AUTOSAR XML (schema 00045)
package /Esh
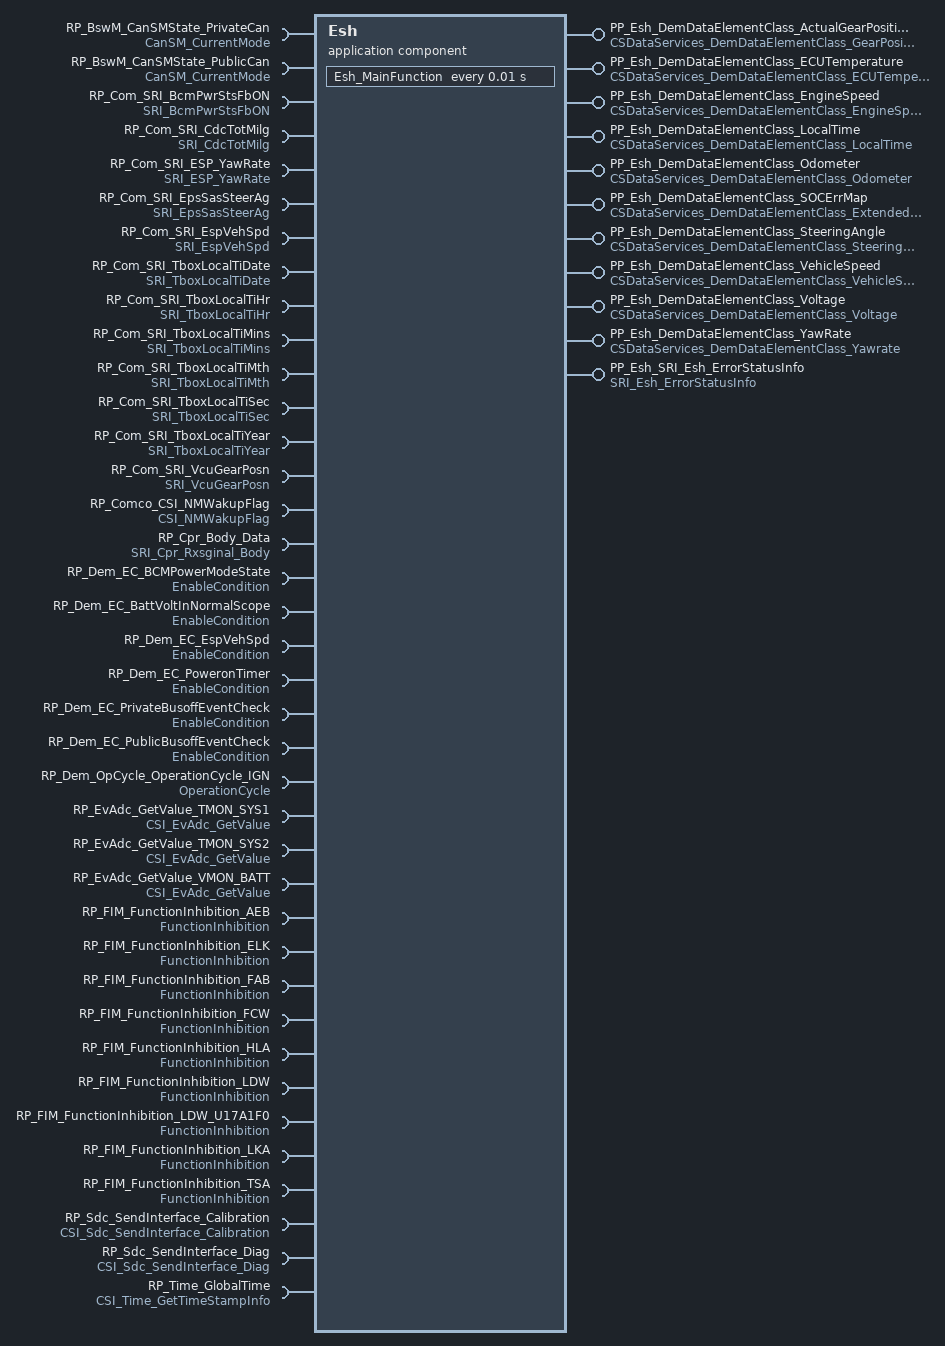
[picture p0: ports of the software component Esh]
  application sw component type Esh
    11 x provide port:
      PP_Esh_DemDataElementClass_ActualGearPosition: provided-interface=CSDataServices_DemDataElementClass_GearPosition
      PP_Esh_DemDataElementClass_ECUTemperature: provided-interface=CSDataServices_DemDataElementClass_ECUTemperature
      PP_Esh_DemDataElementClass_EngineSpeed: provided-interface=CSDataServices_DemDataElementClass_EngineSpeed
      PP_Esh_DemDataElementClass_LocalTime: provided-interface=CSDataServices_DemDataElementClass_LocalTime
      PP_Esh_DemDataElementClass_Odometer: provided-interface=CSDataServices_DemDataElementClass_Odometer
      PP_Esh_DemDataElementClass_SOCErrMap: provided-interface=CSDataServices_DemDataElementClass_Extended_SystemKernelErrMap
      PP_Esh_DemDataElementClass_SteeringAngle: provided-interface=CSDataServices_DemDataElementClass_SteeringAngle
      PP_Esh_DemDataElementClass_VehicleSpeed: provided-interface=CSDataServices_DemDataElementClass_VehicleSpeed
      PP_Esh_DemDataElementClass_Voltage: provided-interface=CSDataServices_DemDataElementClass_Voltage
      PP_Esh_DemDataElementClass_YawRate: provided-interface=CSDataServices_DemDataElementClass_Yawrate
      PP_Esh_SRI_Esh_ErrorStatusInfo: provided-interface=SRI_Esh_ErrorStatusInfo
    38 x require port:
      RP_BswM_CanSMState_PrivateCan: required-interface=CanSM_CurrentMode
      RP_BswM_CanSMState_PublicCan: required-interface=CanSM_CurrentMode
      RP_Com_SRI_BcmPwrStsFbON: required-interface=SRI_BcmPwrStsFbON
      RP_Com_SRI_CdcTotMilg: required-interface=SRI_CdcTotMilg
      RP_Com_SRI_ESP_YawRate: required-interface=SRI_ESP_YawRate
      RP_Com_SRI_EpsSasSteerAg: required-interface=SRI_EpsSasSteerAg
      RP_Com_SRI_EspVehSpd: required-interface=SRI_EspVehSpd
      RP_Com_SRI_TboxLocalTiDate: required-interface=SRI_TboxLocalTiDate
      RP_Com_SRI_TboxLocalTiHr: required-interface=SRI_TboxLocalTiHr
      RP_Com_SRI_TboxLocalTiMins: required-interface=SRI_TboxLocalTiMins
      RP_Com_SRI_TboxLocalTiMth: required-interface=SRI_TboxLocalTiMth
      RP_Com_SRI_TboxLocalTiSec: required-interface=SRI_TboxLocalTiSec
      RP_Com_SRI_TboxLocalTiYear: required-interface=SRI_TboxLocalTiYear
      RP_Com_SRI_VcuGearPosn: required-interface=SRI_VcuGearPosn
      RP_Comco_CSI_NMWakupFlag: required-interface=CSI_NMWakupFlag
      RP_Cpr_Body_Data: required-interface=SRI_Cpr_Rxsginal_Body
      RP_Dem_EC_BCMPowerModeState: required-interface=EnableCondition
      RP_Dem_EC_BattVoltInNormalScope: required-interface=EnableCondition
      RP_Dem_EC_EspVehSpd: required-interface=EnableCondition
      RP_Dem_EC_PoweronTimer: required-interface=EnableCondition
      RP_Dem_EC_PrivateBusoffEventCheck: required-interface=EnableCondition
      RP_Dem_EC_PublicBusoffEventCheck: required-interface=EnableCondition
      RP_Dem_OpCycle_OperationCycle_IGN: required-interface=OperationCycle
      RP_EvAdc_GetValue_TMON_SYS1: required-interface=CSI_EvAdc_GetValue
      RP_EvAdc_GetValue_TMON_SYS2: required-interface=CSI_EvAdc_GetValue
      RP_EvAdc_GetValue_VMON_BATT: required-interface=CSI_EvAdc_GetValue
      RP_FIM_FunctionInhibition_AEB: required-interface=FunctionInhibition
      RP_FIM_FunctionInhibition_ELK: required-interface=FunctionInhibition
      RP_FIM_FunctionInhibition_FAB: required-interface=FunctionInhibition
      RP_FIM_FunctionInhibition_FCW: required-interface=FunctionInhibition
      RP_FIM_FunctionInhibition_HLA: required-interface=FunctionInhibition
      RP_FIM_FunctionInhibition_LDW: required-interface=FunctionInhibition
      RP_FIM_FunctionInhibition_LDW_U17A1F0: required-interface=FunctionInhibition
      RP_FIM_FunctionInhibition_LKA: required-interface=FunctionInhibition
      RP_FIM_FunctionInhibition_TSA: required-interface=FunctionInhibition
      RP_Sdc_SendInterface_Calibration: required-interface=CSI_Sdc_SendInterface_Calibration
      RP_Sdc_SendInterface_Diag: required-interface=CSI_Sdc_SendInterface_Diag
      RP_Time_GlobalTime: required-interface=CSI_Time_GetTimeStampInfo
    behavior Esh_IB: data-type-mapping=DataTypeMappingSet_CanSM, handle-termination-and-restart=NO-SUPPORT
      init event InitEvent_Esh_InitFunction: start-on-event=Esh_InitFunction
      timing event TimingEvent_Esh_MainFunction: start-on-event=Esh_MainFunction, period=0.01
      10 x operation invoked event:
        oie_PP_Dem_DemDataElementClass_ActualGearPosition_ReadData: start-on-event=Esh_u_DataElementClass_ActualGearPosition, operation=PP_Esh_DemDataElementClass_ActualGearPosition.ReadData
        oie_PP_Dem_DemDataElementClass_EngineSpeed_ReadData: start-on-event=Esh_u_DataElementClass_EngineSpeed, operation=PP_Esh_DemDataElementClass_EngineSpeed.ReadData
        oie_PP_Dem_DemDataElementClass_LocalTime_ReadData: start-on-event=Esh_u_DataElementClass_LocalTime, operation=PP_Esh_DemDataElementClass_LocalTime.ReadData
        oie_PP_Dem_DemDataElementClass_Odometer_ReadData: start-on-event=Esh_u_DataElementClass_Odometer, operation=PP_Esh_DemDataElementClass_Odometer.ReadData
        oie_PP_Dem_DemDataElementClass_SOCErrMap_ReadData: start-on-event=Esh_u_DataElementClass_SOCErrMap, operation=PP_Esh_DemDataElementClass_SOCErrMap.ReadData
        oie_PP_Dem_DemDataElementClass_SteeringAngle_ReadData: start-on-event=Esh_u_DataElementClass_SteeringAngle, operation=PP_Esh_DemDataElementClass_SteeringAngle.ReadData
        oie_PP_Dem_DemDataElementClass_VehicleSpeed_ReadData: start-on-event=Esh_u_DataElementClass_VehicleSpeed, operation=PP_Esh_DemDataElementClass_VehicleSpeed.ReadData
        oie_PP_Dem_DemDataElementClass_Voltage_ReadData: start-on-event=Esh_u_DataElementClass_Voltage, operation=PP_Esh_DemDataElementClass_Voltage.ReadData
        oie_PP_Esh_DemDataElementClass_ECUTemperature_ReadData: start-on-event=Esh_u_DataElementClass_ECUTemperature, operation=PP_Esh_DemDataElementClass_ECUTemperature.ReadData
        oie_PP_Esh_DemDataElementClass_YawRate_ReadData: start-on-event=Esh_u_DataElementClass_YawRate, operation=PP_Esh_DemDataElementClass_YawRate.ReadData
      12 x runnable:
        Esh_InitFunction
        Esh_MainFunction
          data-receive-point-by-arguments:
            4 x access:
              drparg_AccIaccHWAMode: accessed-variable=RP_Cpr_Body_Data.AccIaccHWAMode
              drparg_AccIaccHWAMode_Status: accessed-variable=RP_Cpr_Body_Data.AccIaccHWAMode_Status
              drparg_DE_BcmPwrStsFbON: accessed-variable=RP_Com_SRI_BcmPwrStsFbON.DE_BcmPwrStsFbON
              drparg_DE_EspVehSpd: accessed-variable=RP_Com_SRI_EspVehSpd.DE_EspVehSpd
          data-send-points:
            access dsp_DE_Esh_ErrorStatusInfo: accessed-variable=PP_Esh_SRI_Esh_ErrorStatusInfo.DE_Esh_ErrorStatusInfo
          mode-access-points:
            RP_BswM_CanSMState_PublicCan.proto_CANSM_ModeGroup
            RP_BswM_CanSMState_PrivateCan.proto_CANSM_ModeGroup
          20 x sync call, all with timeout=0.0:
            scp_GetFunctionPermission: operation=RP_FIM_FunctionInhibition_AEB.GetFunctionPermission
            scp_GetFunctionPermission0: operation=RP_FIM_FunctionInhibition_ELK.GetFunctionPermission
            scp_GetFunctionPermission1: operation=RP_FIM_FunctionInhibition_FCW.GetFunctionPermission
            scp_GetFunctionPermission2: operation=RP_FIM_FunctionInhibition_HLA.GetFunctionPermission
            scp_GetFunctionPermission3: operation=RP_FIM_FunctionInhibition_LDW.GetFunctionPermission
            scp_GetFunctionPermission4: operation=RP_FIM_FunctionInhibition_LKA.GetFunctionPermission
            scp_GetFunctionPermission5: operation=RP_FIM_FunctionInhibition_TSA.GetFunctionPermission
            scp_GetFunctionPermission6: operation=RP_FIM_FunctionInhibition_FAB.GetFunctionPermission
            scp_GetFunctionPermission7: operation=RP_FIM_FunctionInhibition_LDW_U17A1F0.GetFunctionPermission
            scp_GetPhyValue: operation=RP_EvAdc_GetValue_VMON_BATT.GetPhyValue
            scp_GetTimeStampMs: operation=RP_Time_GlobalTime.GetTimeStampMs
            scp_NMWakupFlag: operation=RP_Comco_CSI_NMWakupFlag.NMWakupFlag
            scp_RequestCalibrationValue: operation=RP_Sdc_SendInterface_Calibration.RequestCalibrationValue
            scp_SetEnableCondition: operation=RP_Dem_EC_PoweronTimer.SetEnableCondition
            scp_SetEnableCondition0: operation=RP_Dem_EC_BattVoltInNormalScope.SetEnableCondition
            scp_SetEnableCondition1: operation=RP_Dem_EC_PublicBusoffEventCheck.SetEnableCondition
            scp_SetEnableCondition2: operation=RP_Dem_EC_PrivateBusoffEventCheck.SetEnableCondition
            scp_SetEnableCondition3: operation=RP_Dem_EC_BCMPowerModeState.SetEnableCondition
            scp_SetEnableCondition4: operation=RP_Dem_EC_EspVehSpd.SetEnableCondition
            scp_SetOperationCycleState: operation=RP_Dem_OpCycle_OperationCycle_IGN.SetOperationCycleState
        Esh_u_DataElementClass_ActualGearPosition
          data-receive-point-by-arguments:
            access drparg_DE_VcuGearPosn: accessed-variable=RP_Com_SRI_VcuGearPosn.DE_VcuGearPosn
        Esh_u_DataElementClass_ECUTemperature
          sync call scp_GetRegValue: operation=RP_EvAdc_GetValue_TMON_SYS1.GetRegValue, timeout=0.0
          sync call scp_GetRegValue0: operation=RP_EvAdc_GetValue_TMON_SYS2.GetRegValue, timeout=0.0
        Esh_u_DataElementClass_EngineSpeed
        Esh_u_DataElementClass_LocalTime
          data-receive-point-by-arguments:
            6 x access:
              drparg_DE_TboxLocalTiDate: accessed-variable=RP_Com_SRI_TboxLocalTiDate.DE_TboxLocalTiDate
              drparg_DE_TboxLocalTiHr: accessed-variable=RP_Com_SRI_TboxLocalTiHr.DE_TboxLocalTiHr
              drparg_DE_TboxLocalTiMins: accessed-variable=RP_Com_SRI_TboxLocalTiMins.DE_TboxLocalTiMins
              drparg_DE_TboxLocalTiMth: accessed-variable=RP_Com_SRI_TboxLocalTiMth.DE_TboxLocalTiMth
              drparg_DE_TboxLocalTiSec: accessed-variable=RP_Com_SRI_TboxLocalTiSec.DE_TboxLocalTiSec
              drparg_DE_TboxLocalTiYear: accessed-variable=RP_Com_SRI_TboxLocalTiYear.DE_TboxLocalTiYear
        Esh_u_DataElementClass_Odometer
          data-receive-point-by-arguments:
            access drparg_DE_CdcTotMilg: accessed-variable=RP_Com_SRI_CdcTotMilg.DE_CdcTotMilg
        Esh_u_DataElementClass_SOCErrMap
          sync call scp_SocDiagInfo_Read: operation=RP_Sdc_SendInterface_Diag.SocDiagInfo_Read, timeout=0.0
        Esh_u_DataElementClass_SteeringAngle
          data-receive-point-by-arguments:
            access drparg_DE_EpsSasSteerAg: accessed-variable=RP_Com_SRI_EpsSasSteerAg.DE_EpsSasSteerAg
        Esh_u_DataElementClass_VehicleSpeed
          data-receive-point-by-arguments:
            access drparg_DE_EspVehSpd: accessed-variable=RP_Com_SRI_EspVehSpd.DE_EspVehSpd
        Esh_u_DataElementClass_Voltage
          sync call scp_GetPhyValue: operation=RP_EvAdc_GetValue_VMON_BATT.GetPhyValue, timeout=0.0
        Esh_u_DataElementClass_YawRate
          data-receive-point-by-arguments:
            access drparg_DE_ESP_YawRate: accessed-variable=RP_Com_SRI_ESP_YawRate.DE_ESP_YawRate
  swc implementation Esh_Impl: programming-language=C, sw-version=1.0.0, vendor-id=0, behavior=Esh_IB
    code-descriptors:
      code CD_Esh: artifact-descriptors=[{short-label=SWSRC, category=SWSRC}, {short-label=SWHDR, category=SWHDR}]
    resource consumption Resource
      memory section CODE: sw-addrmethod=CODE
      memory section VAR_UNSPECIFIED: sw-addrmethod=VAR
  sender receiver interface SRI_Esh_ErrorStatusInfo
    data DE_Esh_ErrorStatusInfo: type=s_Esh_ErrorStatusInfo_t
  impl type s_Esh_ErrorStatusInfo_t: category=STRUCTURE
    8 x element, all with category=TYPE_REFERENCE, implementation-data-type=boolean:
      AEB
      ELK
      FCW
      HLA
      LDW
      LKA
      TSA
      FAB
